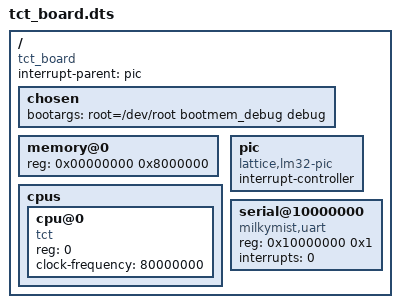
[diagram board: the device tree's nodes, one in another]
/dts-v1/;
/ {
	compatible = "tct_board";
	#address-cells = <1>;
	#size-cells = <1>;
	interrupt-parent = <&pic>; 

	chosen {
		bootargs = "root=/dev/root bootmem_debug debug";
	};

	memory@0 {
		device_type = "memory";
		reg = <0x00000000 0x8000000>; 
	};

	cpus {
		#address-cells = <1>;
		#size-cells = <0>;
		cpu@0 {
			compatible = "tct";
			reg = <0>;
			clock-frequency = <80000000>; 
		};
	};

	pic: pic {
		compatible = "lattice,lm32-pic";
		#interrupt-cells = <1>;
		interrupt-controller;
	};

	serial@10000000 {
		compatible = "milkymist,uart";
		reg = <0x10000000 0x1>;
		interrupts = <0>;
	};
};
